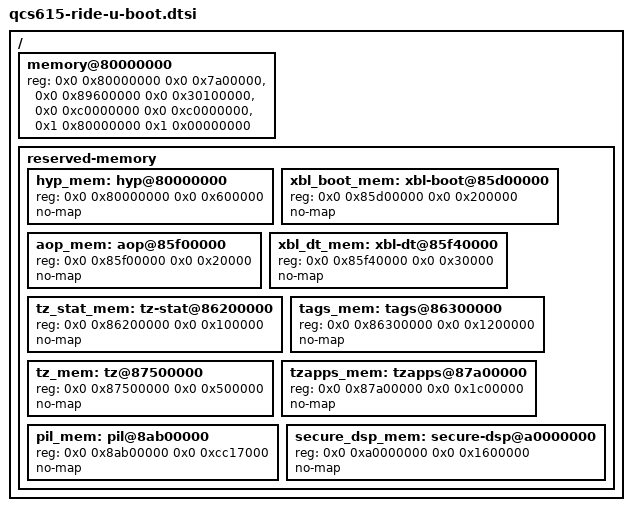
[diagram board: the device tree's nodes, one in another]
// SPDX-License-Identifier: BSD-3-Clause
/*
 * Copyright (c) 2025, Qualcomm Innovation Center, Inc. All rights reserved.
 */

/ {
	memory@80000000 {
		device_type = "memory";
		reg = <0x0 0x80000000 0x0 0x7a00000>,
		      <0x0 0x89600000 0x0 0x30100000>,
		      <0x0 0xc0000000 0x0 0xc0000000>,
		      <0x1 0x80000000 0x1 0x00000000>;
	};

	reserved-memory {
		#address-cells = <2>;
		#size-cells = <2>;
		ranges;

		hyp_mem: hyp@80000000 {
			reg = <0x0 0x80000000 0x0 0x600000>;
			no-map;
		};

		xbl_boot_mem: xbl-boot@85d00000 {
			reg = <0x0 0x85d00000 0x0 0x200000>;
			no-map;
		};

		aop_mem: aop@85f00000 {
			reg = <0x0 0x85f00000 0x0 0x20000>;
			no-map;
		};

		xbl_dt_mem: xbl-dt@85f40000 {
			reg = <0x0 0x85f40000 0x0 0x30000>;
			no-map;
		};

		tz_stat_mem: tz-stat@86200000 {
			reg = <0x0 0x86200000 0x0 0x100000>;
			no-map;
		};

		tags_mem: tags@86300000 {
			reg = <0x0 0x86300000 0x0 0x1200000>;
			no-map;
		};

		tz_mem: tz@87500000 {
			reg = <0x0 0x87500000 0x0 0x500000>;
			no-map;
		};

		tzapps_mem: tzapps@87a00000 {
			reg = <0x0 0x87a00000 0x0 0x1c00000>;
			no-map;
		};

		pil_mem: pil@8ab00000 {
			reg = <0x0 0x8ab00000 0x0 0xcc17000>;
			no-map;
		};

		secure_dsp_mem: secure-dsp@a0000000 {
			reg = <0x0 0xa0000000 0x0 0x1600000>;
			no-map;
		};
	};
};
